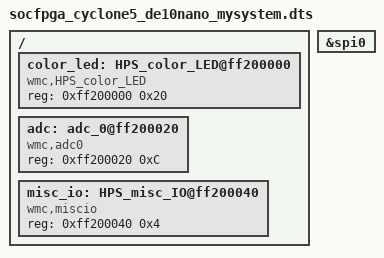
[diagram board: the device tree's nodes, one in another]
#include "socfpga_cyclone5_de0.dtsi"

/{
    color_led: HPS_color_LED@ff200000 {
	    compatible = "wmc,HPS_color_LED";
	    reg = <0xff200000 0x20>;
    };
    adc: adc_0@ff200020 {
	    compatible = "wmc,adc0";
	    reg = <0xff200020 0xC>;
    };
    misc_io: HPS_misc_IO@ff200040 {
	    compatible = "wmc,miscio";
	    reg = <0xff200040 0x4>;
    };
};

&spi0 {
    status = "okay";
};

